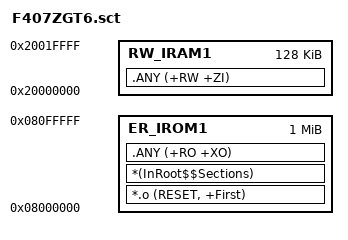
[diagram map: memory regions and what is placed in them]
; ******************************************************************
; *** Scatter-Loading Description File generated by Embedded IDE ***
; ******************************************************************

LR_IROM1 0x08000000 0x00100000  {               ; 1MB Flash
  ER_IROM1 0x08000000 0x00100000  {             ; Code + RO
    *.o (RESET, +First)                          ; 启动向量
    *(InRoot$$Sections)
    .ANY (+RO +XO)
  }
  RW_IRAM1 0x20000000 0x00020000  {             ; 128KB SRAM (可按需调)
    .ANY (+RW +ZI)
  }
  ; 如需使用 CCM 64KB 可加:
  ; RW_IRAM2 0x10000000 0x00010000  {
  ;   .ANY (+RW +ZI)
  ; }
}

